# BlueNRG_LP register map
File version: 1.0
CPU: CM0+ r0p0, little endian, no MPU, no FPU, 2 interrupt priority bits
Registers are 32-bit, read-write, reset 0x0 unless marked. A register's access mark holds for its fields unless they carry their own. Offsets are from the block's base; [hi:lo] are bit positions; {n}, {i} and the like mark numbered series.

## DMAMUX — Direct memory access Multiplexer
Base 0x48800000
{0x0+4i} C{i}CR (i=0..7) — DMA Multiplexer Channel {i} Control register
  [4:0] DMAREQ_ID — DMA Request ID

## FLASH
Base 0x40001000
0x00 COMMAND
  [7:0] COMMAND — Command opcode to launch any operation on Flash memory. See for command list and detail.
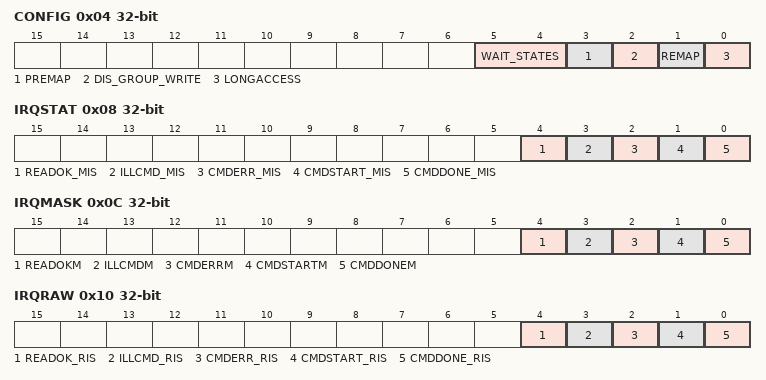
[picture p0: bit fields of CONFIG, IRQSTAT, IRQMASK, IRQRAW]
0x04 CONFIG — Configuration register
  [5:4] WAIT_STATES — Number of wait states to be inserted on Flash read (AHB accesses).
  [3] PREMAP — bit to redirect boot area on IFR or main Flash.
  [2] DIS_GROUP_WRITE
  [1] REMAP — bit to redirect boot area on SRAM0.
  [0] LONGACCESS — debug and test only
0x08 IRQSTAT — The interrupt status register shows the masked version of the interrupt raw register.
  [4] READOK_MIS — Mass read OK masked interrupt status.
  [3] ILLCMD_MIS — Illegal command masked interrupt status.
  [2] CMDERR_MIS — command error masked interrupt status.
  [1] CMDSTART_MIS — Command started masked interrupt status.
  [0] CMDDONE_MIS — Command done masked interrupt status.
0x0C IRQMASK — The mask bit in IRQMASK will mask the condition in the status register IRQSTAT and prevent the generation of the interrupt.
  [4] READOKM — Mass read OK mask.
  [3] ILLCMDM — Illegal command mask.
  [2] CMDERRM — command error mask.
  [1] CMDSTARTM — Command started mask.
  [0] CMDDONEM — Command done mask.
0x10 IRQRAW — The raw status register shows the unmasked condition of interrupt events.
  [4] READOK_RIS — Mass read OK raw/unmasked interrupt status.
  [3] ILLCMD_RIS — Illegal command raw/unmasked interrupt status.
  [2] CMDERR_RIS — command error raw/unmasked interrupt status.
  [1] CMDSTART_RIS — Command started raw/unmasked interrupt status.
  [0] CMDDONE_RIS — Command done raw/unmasked interrupt status.
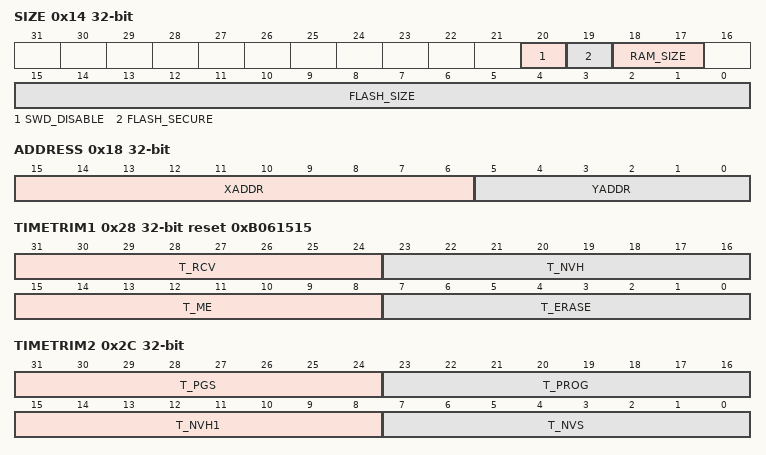
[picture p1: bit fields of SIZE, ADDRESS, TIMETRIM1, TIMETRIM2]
0x14 SIZE
  [20] SWD_DISABLE — indicates the SWD JTAG is disabled on the device
  [19] FLASH_SECURE — indicates the main FLASH is locked by a customer key.
  [18:17] RAM_SIZE — indicates the size of RAM available in the device
  [15:0] FLASH_SIZE — indicates the last usable address of the Flash using memory component address format.
0x18 ADDRESS
  [15:6] XADDR — page number (from 0 to 127) row number (from 0 to 7)
  [5:0] YADDR — word number inside the selected row (from 0 to 63)
0x24 LFSRVAL ro — Linear Feedback Shift register contains the signature issued by a MASSREAD command.
  [31:0] LFSRVAL — signature after a MASSREAD command, generated through a Linear Feedback Shift Register block
0x28 TIMETRIM1 reset 0xB061515 — Time trim registers 1
  [31:24] T_RCV — Recovery time.
  [23:16] T_NVH — NVSTR hold time.
  [15:8] T_ME — Mass erase time.
  [7:0] T_ERASE — Page erase time.
0x2C TIMETRIM2 — Time trim registers 2
  [31:24] T_PGS — NVSTR to PROGRAM setup time
  [23:16] T_PROG — Program time
  [15:8] T_NVH1 — NVSTR hold time for mass erase
  [7:0] T_NVS — NVSTR setup time
0x30 TIMETRIM3 — Time trim registers 3
  [7:0] T_WK — Wakeup time.
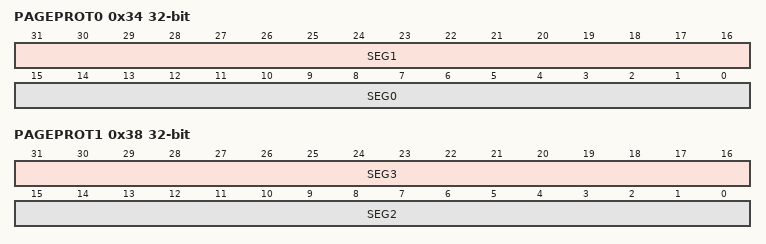
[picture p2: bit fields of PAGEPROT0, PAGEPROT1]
0x34 PAGEPROT0 — The PAGEPROTx registers allows protecting from accidental write a contiguous set of pages called segment in the following description.
  [31:16] SEG1 — second segment definition.
  [15:0] SEG0 — First segment definition.
0x38 PAGEPROT1 — The PAGEPROTx registers allows protecting from accidental write a contiguous set of pages called segment in the following description.
  [31:16] SEG3 — fourth segment definition.
  [15:0] SEG2 — third segment definition.
0x40 DATA0 — Data register 0
  [31:0] DATA0 — this register has several usage
0x44 DATA1 — Data register 1
  [31:0] DATA1 — data that will be written at ADDRESS+1 during a BURSTWRITE command.
0x48 DATA2 — Data register 2
  [31:0] DATA2 — data that will be written at ADDRESS+2 during a BURSTWRITE command
0x4C DATA3 — Data register 3
  [31:0] DATA3 — data that will be written at ADDRESS+3 during a BURSTWRITE command.
